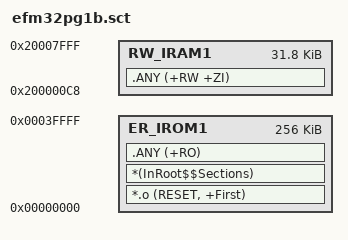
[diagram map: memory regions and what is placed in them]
#! armcc -E
; *************************************************************
; *** Scatter-Loading Description File generated by uVision ***
; *************************************************************

#if !defined(MBED_APP_START)
  #define MBED_APP_START 0x00000000
#endif

#if !defined(MBED_APP_SIZE)
  #define MBED_APP_SIZE 0x00040000
#endif

LR_IROM1 MBED_APP_START MBED_APP_SIZE  {    ; load region size_region
  ER_IROM1 MBED_APP_START MBED_APP_SIZE  {  ; load address = execution address
   *.o (RESET, +First)
   *(InRoot$$Sections)
   .ANY (+RO)
  }
  RW_IRAM1 0x200000C8 0x00007F38  {  ; RW data
   .ANY (+RW +ZI)
  }
}

